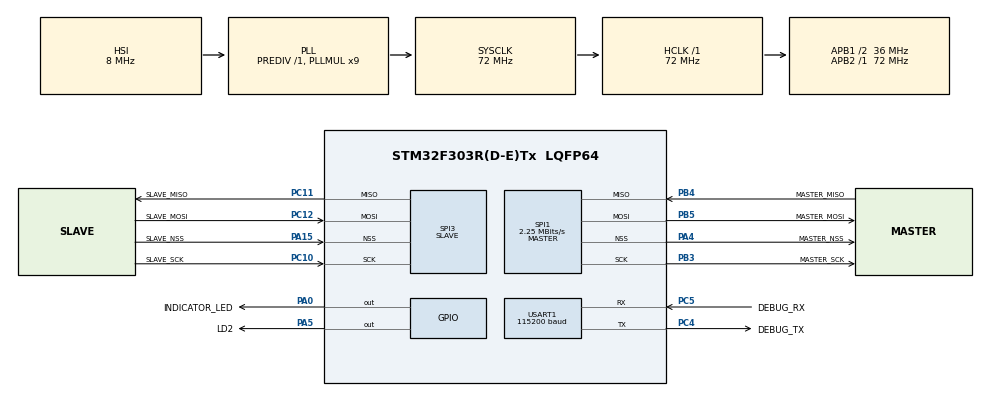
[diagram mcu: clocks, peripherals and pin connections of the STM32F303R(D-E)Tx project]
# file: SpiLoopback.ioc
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Dma.Request0=USART1_RX
Dma.Request1=USART1_TX
Dma.Request2=SPI1_TX
Dma.Request3=SPI1_RX
Dma.Request4=SPI3_RX
Dma.Request5=SPI3_TX
Dma.SPI1_RX.3.Direction=DMA_PERIPH_TO_MEMORY
Dma.SPI1_RX.3.Instance=DMA1_Channel2
Dma.SPI1_RX.3.MemDataAlignment=DMA_MDATAALIGN_BYTE
Dma.SPI1_RX.3.MemInc=DMA_MINC_ENABLE
Dma.SPI1_RX.3.Mode=DMA_NORMAL
Dma.SPI1_RX.3.PeriphDataAlignment=DMA_PDATAALIGN_BYTE
Dma.SPI1_RX.3.PeriphInc=DMA_PINC_DISABLE
Dma.SPI1_RX.3.Priority=DMA_PRIORITY_LOW
Dma.SPI1_TX.2.Direction=DMA_MEMORY_TO_PERIPH
Dma.SPI1_TX.2.Instance=DMA1_Channel3
Dma.SPI1_TX.2.MemDataAlignment=DMA_MDATAALIGN_BYTE
Dma.SPI1_TX.2.MemInc=DMA_MINC_ENABLE
Dma.SPI1_TX.2.Mode=DMA_NORMAL
Dma.SPI1_TX.2.PeriphDataAlignment=DMA_PDATAALIGN_BYTE
Dma.SPI1_TX.2.PeriphInc=DMA_PINC_DISABLE
Dma.SPI1_TX.2.Priority=DMA_PRIORITY_LOW
Dma.SPI3_RX.4.Direction=DMA_PERIPH_TO_MEMORY
Dma.SPI3_RX.4.Instance=DMA2_Channel1
Dma.SPI3_RX.4.MemDataAlignment=DMA_MDATAALIGN_BYTE
Dma.SPI3_RX.4.MemInc=DMA_MINC_ENABLE
Dma.SPI3_RX.4.Mode=DMA_NORMAL
Dma.SPI3_RX.4.PeriphDataAlignment=DMA_PDATAALIGN_BYTE
Dma.SPI3_RX.4.PeriphInc=DMA_PINC_DISABLE
Dma.SPI3_RX.4.Priority=DMA_PRIORITY_LOW
Dma.SPI3_TX.5.Direction=DMA_MEMORY_TO_PERIPH
Dma.SPI3_TX.5.Instance=DMA2_Channel2
Dma.SPI3_TX.5.MemDataAlignment=DMA_MDATAALIGN_BYTE
Dma.SPI3_TX.5.MemInc=DMA_MINC_ENABLE
Dma.SPI3_TX.5.Mode=DMA_NORMAL
Dma.SPI3_TX.5.PeriphDataAlignment=DMA_PDATAALIGN_BYTE
Dma.SPI3_TX.5.PeriphInc=DMA_PINC_DISABLE
Dma.SPI3_TX.5.Priority=DMA_PRIORITY_LOW
Dma.USART1_RX.0.Direction=DMA_PERIPH_TO_MEMORY
Dma.USART1_RX.0.Instance=DMA1_Channel5
Dma.USART1_RX.0.MemDataAlignment=DMA_MDATAALIGN_BYTE
Dma.USART1_RX.0.MemInc=DMA_MINC_ENABLE
Dma.USART1_RX.0.Mode=DMA_NORMAL
Dma.USART1_RX.0.PeriphDataAlignment=DMA_PDATAALIGN_BYTE
Dma.USART1_RX.0.PeriphInc=DMA_PINC_DISABLE
Dma.USART1_RX.0.Priority=DMA_PRIORITY_LOW
Dma.USART1_TX.1.Direction=DMA_MEMORY_TO_PERIPH
Dma.USART1_TX.1.Instance=DMA1_Channel4
Dma.USART1_TX.1.MemDataAlignment=DMA_MDATAALIGN_BYTE
Dma.USART1_TX.1.MemInc=DMA_MINC_ENABLE
Dma.USART1_TX.1.Mode=DMA_NORMAL
Dma.USART1_TX.1.PeriphDataAlignment=DMA_PDATAALIGN_BYTE
Dma.USART1_TX.1.PeriphInc=DMA_PINC_DISABLE
Dma.USART1_TX.1.Priority=DMA_PRIORITY_LOW
Mcu.Family=STM32F3
Mcu.Name=STM32F303R(D-E)Tx
Mcu.Package=LQFP64
NVIC.DMA1_Channel2_IRQn=true\:0\:0\:false\:false\:true\:false\:true\:true
NVIC.DMA1_Channel3_IRQn=true\:0\:0\:false\:false\:true\:false\:true\:true
NVIC.DMA1_Channel4_IRQn=true\:2\:0\:true\:false\:true\:false\:true\:true
NVIC.DMA1_Channel5_IRQn=true\:3\:0\:true\:false\:true\:false\:true\:true
NVIC.DMA2_Channel1_IRQn=true\:0\:0\:false\:false\:true\:false\:true\:true
NVIC.DMA2_Channel2_IRQn=true\:0\:0\:false\:false\:true\:false\:true\:true
NVIC.PriorityGroup=NVIC_PRIORITYGROUP_4
NVIC.RCC_IRQn=true\:0\:0\:false\:false\:true\:true\:false\:true
NVIC.SPI1_IRQn=true\:7\:0\:true\:false\:true\:true\:true\:true
NVIC.SPI3_IRQn=true\:0\:0\:false\:false\:true\:true\:true\:true
NVIC.USART1_IRQn=true\:0\:0\:false\:false\:true\:true\:true\:true
PA0.GPIO_Label=INDICATOR_LED
PA0.PinState=GPIO_PIN_SET
PA0.Signal=GPIO_Output
PA13.Mode=Serial_Wire
PA13.Signal=SYS_JTMS-SWDIO
PA14.Mode=Serial_Wire
PA14.Signal=SYS_JTCK-SWCLK
PA15.GPIO_Label=SLAVE_NSS
PA15.Mode=NSS_Signal_Hard_Input
PA15.Signal=SPI3_NSS
PA2.Signal=USART2_TX
PA3.Signal=USART2_RX
PA4.GPIO_Label=MASTER_NSS
PA4.Mode=NSS_Signal_Hard_Output
PA4.Signal=SPI1_NSS
PA5.GPIO_Label=LD2
PA5.GPIO_ModeDefaultOutputPP=GPIO_MODE_OUTPUT_PP
PA5.GPIO_PuPd=GPIO_NOPULL
PA5.PinState=GPIO_PIN_SET
PA5.Signal=GPIO_Output
PB3.GPIO_Label=MASTER_SCK
PB3.Mode=Full_Duplex_Master
PB3.Signal=SPI1_SCK
PB4.GPIO_Label=MASTER_MISO
PB4.Mode=Full_Duplex_Master
PB4.Signal=SPI1_MISO
PB5.GPIO_Label=MASTER_MOSI
PB5.Mode=Full_Duplex_Master
PB5.Signal=SPI1_MOSI
PC10.GPIO_Label=SLAVE_SCK
PC10.Mode=Full_Duplex_Slave
PC10.Signal=SPI3_SCK
PC11.GPIO_Label=SLAVE_MISO
PC11.Mode=Full_Duplex_Slave
PC11.Signal=SPI3_MISO
PC12.GPIO_Label=SLAVE_MOSI
PC12.Mode=Full_Duplex_Slave
PC12.Signal=SPI3_MOSI
PC4.GPIO_Label=DEBUG_TX
PC4.Mode=Asynchronous
PC4.Signal=USART1_TX
PC5.GPIO_Label=DEBUG_RX
PC5.Mode=Asynchronous
PC5.Signal=USART1_RX
ProjectManager.HeapSize=0x200
ProjectManager.StackSize=0x800
ProjectManager.TargetToolchain=Makefile
RCC.AHBFreq_Value=72000000
RCC.APB1CLKDivider=RCC_HCLK_DIV2
RCC.APB1Freq_Value=36000000
RCC.APB1TimFreq_Value=72000000
RCC.APB2Freq_Value=72000000
RCC.APB2TimFreq_Value=72000000
RCC.CortexFreq_Value=72000000
RCC.HCLKFreq_Value=72000000
RCC.HSE_VALUE=8000000
RCC.HSI_VALUE=8000000
RCC.LSE_VALUE=32768
RCC.PLLMUL=RCC_PLL_MUL9
RCC.SYSCLKFreq_VALUE=72000000
RCC.SYSCLKSourceVirtual=RCC_SYSCLKSOURCE_PLLCLK
RCC.USBFreq_Value=72000000
RCC.Usart1ClockSelection=RCC_USART1CLKSOURCE_SYSCLK
SPI1.BaudRatePrescaler=SPI_BAUDRATEPRESCALER_32
SPI1.CLKPhase=SPI_PHASE_1EDGE
SPI1.CRCCalculation=SPI_CRCCALCULATION_DISABLE
SPI1.CalculateBaudRate=2.25 MBits/s
SPI1.DataSize=SPI_DATASIZE_8BIT
SPI1.Direction=SPI_DIRECTION_2LINES
SPI1.Mode=SPI_MODE_MASTER
SPI1.TIMode=SPI_TIMODE_DISABLE
SPI1.VirtualNSS=VM_NSSHARD
SPI1.VirtualType=VM_MASTER
SPI3.DataSize=SPI_DATASIZE_8BIT
SPI3.Direction=SPI_DIRECTION_2LINES
SPI3.Mode=SPI_MODE_SLAVE
SPI3.TIMode=SPI_TIMODE_DISABLE
SPI3.VirtualNSS=VM_NSSHARD
SPI3.VirtualType=VM_SLAVE
USART1.BaudRate=115200
USART1.VirtualMode-Asynchronous=VM_ASYNC
board=custom

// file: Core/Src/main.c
/* USER CODE BEGIN Header */
/**
  ******************************************************************************
  * @file           : main.c
  * @brief          : Main program body
  ******************************************************************************
  * @attention
  *
  * Copyright (c) 2022 STMicroelectronics.
  * All rights reserved.
  *
  * This software is licensed under terms that can be found in the LICENSE file
  * in the root directory of this software component.
  * If no LICENSE file comes with this software, it is provided AS-IS.
  *
  ******************************************************************************
  */

#include "SpiLoopback.h"

/* USER CODE END Header */
#include "main.h"
#include "dma.h"
#include "spi.h"
#include "usart.h"
#include "gpio.h"

void SystemClock_Config(void);

int main(void)
{

  /* MCU Configuration--------------------------------------------------------*/

  /* Reset of all peripherals, Initializes the Flash interface and the Systick. */
  HAL_Init();

  /* Configure the system clock */
  SystemClock_Config();

  /* Initialize all configured peripherals */
  MX_GPIO_Init();
  MX_DMA_Init();
  MX_SPI1_Init();
  MX_USART1_UART_Init();
  MX_SPI3_Init();

  /* Infinite loop */
  /* USER CODE BEGIN WHILE */
  while (1)
  {
	MainMasterSlave();

    /* USER CODE END WHILE */

  }
}

void SystemClock_Config(void)
{
  RCC_OscInitTypeDef RCC_OscInitStruct = {0};
  RCC_ClkInitTypeDef RCC_ClkInitStruct = {0};
  RCC_PeriphCLKInitTypeDef PeriphClkInit = {0};

  /** Initializes the RCC Oscillators according to the specified parameters
  * in the RCC_OscInitTypeDef structure.
  */
  RCC_OscInitStruct.OscillatorType = RCC_OSCILLATORTYPE_HSI;
  RCC_OscInitStruct.HSIState = RCC_HSI_ON;
  RCC_OscInitStruct.HSICalibrationValue = RCC_HSICALIBRATION_DEFAULT;
  RCC_OscInitStruct.PLL.PLLState = RCC_PLL_ON;
  RCC_OscInitStruct.PLL.PLLSource = RCC_PLLSOURCE_HSI;
  RCC_OscInitStruct.PLL.PLLMUL = RCC_PLL_MUL9;
  RCC_OscInitStruct.PLL.PREDIV = RCC_PREDIV_DIV1;
  if (HAL_RCC_OscConfig(&RCC_OscInitStruct) != HAL_OK)
  {
    Error_Handler();
  }

  /** Initializes the CPU, AHB and APB buses clocks
  */
  RCC_ClkInitStruct.ClockType = RCC_CLOCKTYPE_HCLK|RCC_CLOCKTYPE_SYSCLK
                              |RCC_CLOCKTYPE_PCLK1|RCC_CLOCKTYPE_PCLK2;
  RCC_ClkInitStruct.SYSCLKSource = RCC_SYSCLKSOURCE_PLLCLK;
  RCC_ClkInitStruct.AHBCLKDivider = RCC_SYSCLK_DIV1;
  RCC_ClkInitStruct.APB1CLKDivider = RCC_HCLK_DIV2;
  RCC_ClkInitStruct.APB2CLKDivider = RCC_HCLK_DIV1;

  if (HAL_RCC_ClockConfig(&RCC_ClkInitStruct, FLASH_LATENCY_2) != HAL_OK)
  {
    Error_Handler();
  }
  PeriphClkInit.PeriphClockSelection = RCC_PERIPHCLK_USART1;
  PeriphClkInit.Usart1ClockSelection = RCC_USART1CLKSOURCE_SYSCLK;
  if (HAL_RCCEx_PeriphCLKConfig(&PeriphClkInit) != HAL_OK)
  {
    Error_Handler();
  }
}

void Error_Handler(void)
{
  __disable_irq();
  while (1)
  {
  }
}
